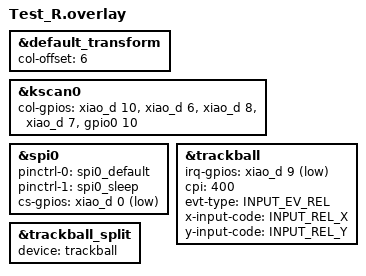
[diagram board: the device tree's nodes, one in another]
#include "Test.dtsi"
#include "Test_trackball.dtsi"

#define INPUT_EV_KEY 0x01               /**< Key event */
#define INPUT_EV_REL 0x02               /**< Relative coordinate event */
#define INPUT_EV_ABS 0x03               /**< Absolute coordinate event */
#define INPUT_EV_MSC 0x04               /**< Miscellaneous event */
#define INPUT_EV_VENDOR_START 0xf0      /**< Vendor specific event start */
#define INPUT_EV_VENDOR_STOP 0xff       /**< Vendor specific event stop */

#define INPUT_REL_X 0x00                /**< Relative X coordinate */
#define INPUT_REL_Y 0x01                /**< Relative Y coordinate */
#define INPUT_REL_WHEEL 0x08            /**< Relative wheel coordinate */
#define INPUT_REL_HWHEEL 0x06           /**< Relative horizontal wheel coordinate */
#define INPUT_REL_MISC 0x09             /**< Relative misc coordinate */

&default_transform {
    col-offset = <6>;
};

&kscan0 {
        col-gpios
            = <&xiao_d 10 GPIO_ACTIVE_HIGH>
            , <&xiao_d 6 GPIO_ACTIVE_HIGH> 
            , <&xiao_d 8 GPIO_ACTIVE_HIGH> 
            , <&xiao_d 7 GPIO_ACTIVE_HIGH> 
            , <&gpio0 10 GPIO_ACTIVE_HIGH>
            ;
};

&spi0 {
    status = "okay";
    pinctrl-0 = <&spi0_default>;
    pinctrl-1 = <&spi0_sleep>;
    pinctrl-names = "default", "sleep";
    cs-gpios = <&xiao_d 0 GPIO_ACTIVE_LOW>;
};

&trackball {
    status = "okay";
	irq-gpios = <&xiao_d 9 (GPIO_ACTIVE_LOW | GPIO_PULL_UP)>;
	cpi = <400>;
	evt-type = <INPUT_EV_REL>;
	x-input-code = <INPUT_REL_X>;
	y-input-code = <INPUT_REL_Y>;
};

&trackball_split {
    device = <&trackball>;
};


